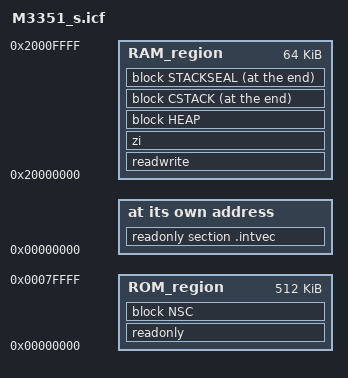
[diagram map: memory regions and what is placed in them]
/*###ICF### Section handled by ICF editor, don't touch! ****/
/*-Editor annotation file-*/
/* IcfEditorFile="$TOOLKIT_DIR$\config\ide\IcfEditor\cortex_v1_0.xml" */
/*-Specials-*/
define symbol __ICFEDIT_intvec_start__ = 0x00000000;

/*-Memory Regions-*/
define symbol __ICFEDIT_region_ROM_start__  = 0x00000000;
define symbol __ICFEDIT_region_ROM_end__    = 0x0007FFFF;

define symbol __ICFEDIT_region_RAM_start__  = 0x20000000;
define symbol __ICFEDIT_region_RAM_end__    = 0x2000FFFF;

/*-Sizes-*/
define symbol __ICFEDIT_size_cstack__ = 0x00001000;
define symbol __ICFEDIT_size_heap__   = 0x00008000;
/**** End of ICF editor section. ###ICF###*/

define memory mem with size = 4G;
define region ROM_region  = mem:[from __ICFEDIT_region_ROM_start__  to __ICFEDIT_region_ROM_end__ ];
define region RAM_region  = mem:[from __ICFEDIT_region_RAM_start__  to __ICFEDIT_region_RAM_end__ ];

define symbol __STACKSEAL_SIZE  = 0x8;      // Size of the stack seal for stack protection.
define symbol __CMSEVENEER_SIZE = 0x200;    // Size of CMSE Veneer region.
define block CSTACK with alignment = 8,  size = ( __ICFEDIT_size_cstack__ - __STACKSEAL_SIZE ) { };
define block HEAP   with alignment = 8,  size = __ICFEDIT_size_heap__   { };
// Defines the Non-Secure Callable (NSC) region for CMSE veneers.
// This block must be 32-byte aligned for the Security Attribution Unit (SAU).
define block NSC    with alignment = 32, size = __CMSEVENEER_SIZE       { section Veneer$$CMSE* };
// The stack seal block, placed directly after the stack
define block STACKSEAL with alignment = 8, size = __STACKSEAL_SIZE { };

initialize by copy { readwrite};
do not initialize  { section .noinit};

place at address mem:__ICFEDIT_intvec_start__ { readonly section .intvec };

place in ROM_region { readonly };
place in ROM_region { block NSC };
place in RAM_region { readwrite, zi, block HEAP };
place at end of RAM_region { block CSTACK, block STACKSEAL };
